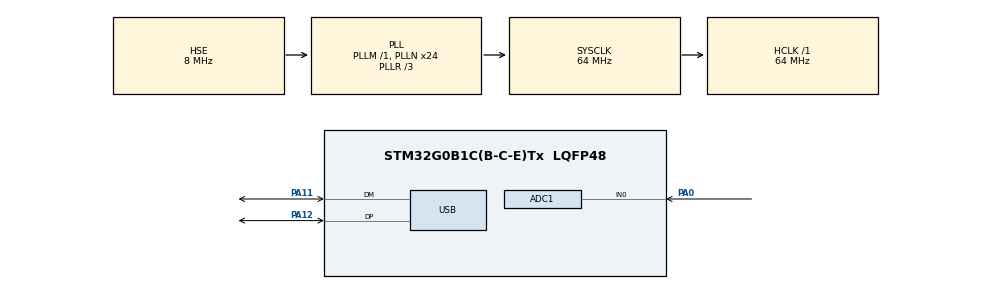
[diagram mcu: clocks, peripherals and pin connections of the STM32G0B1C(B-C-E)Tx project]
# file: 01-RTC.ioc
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ADC1.Channel-1\#ChannelRegularConversion=ADC_CHANNEL_0
ADC1.ContinuousConvMode=ENABLE
ADC1.DMAContinuousRequests=ENABLE
ADC1.NbrOfConversionFlag=1
ADC1.Rank-1\#ChannelRegularConversion=1
ADC1.SamplingTime-1\#ChannelRegularConversion=ADC_SAMPLINGTIME_COMMON_1
ADC1.SamplingTimeCommon1=ADC_SAMPLETIME_160CYCLES_5
ADC1.SamplingTimeCommon2=ADC_SAMPLETIME_160CYCLES_5
ADC1.SelectedChannel=ADC_CHANNEL_0
ADC1.master=1
Dma.ADC1.0.Direction=DMA_PERIPH_TO_MEMORY
Dma.ADC1.0.EventEnable=DISABLE
Dma.ADC1.0.Instance=DMA1_Channel1
Dma.ADC1.0.MemDataAlignment=DMA_MDATAALIGN_HALFWORD
Dma.ADC1.0.MemInc=DMA_MINC_ENABLE
Dma.ADC1.0.Mode=DMA_CIRCULAR
Dma.ADC1.0.PeriphDataAlignment=DMA_PDATAALIGN_HALFWORD
Dma.ADC1.0.PeriphInc=DMA_PINC_DISABLE
Dma.ADC1.0.Polarity=HAL_DMAMUX_REQ_GEN_RISING
Dma.ADC1.0.Priority=DMA_PRIORITY_LOW
Dma.ADC1.0.RequestNumber=1
Dma.ADC1.0.SignalID=NONE
Dma.ADC1.0.SyncEnable=DISABLE
Dma.ADC1.0.SyncPolarity=HAL_DMAMUX_SYNC_NO_EVENT
Dma.ADC1.0.SyncRequestNumber=1
Dma.ADC1.0.SyncSignalID=NONE
Dma.Request0=ADC1
Mcu.Family=STM32G0
Mcu.Name=STM32G0B1C(B-C-E)Tx
Mcu.Package=LQFP48
NVIC.DMA1_Channel1_IRQn=true\:0\:0\:false\:false\:true\:false\:true\:true
NVIC.USB_UCPD1_2_IRQn=true\:0\:0\:false\:false\:true\:true\:true\:true
PA0.Mode=IN0
PA0.Signal=ADC1_IN0
PA11\ [PA9].Mode=Device
PA11\ [PA9].Signal=USB_DM
PA12\ [PA10].Mode=Device
PA12\ [PA10].Signal=USB_DP
PA13.Mode=Serial_Wire
PA13.Signal=SYS_SWDIO
PA14-BOOT0.Mode=Serial_Wire
PA14-BOOT0.Signal=SYS_SWCLK
PC14-OSC32_IN\ (PC14).Mode=LSE-External-Oscillator
PC14-OSC32_IN\ (PC14).Signal=RCC_OSC32_IN
PC15-OSC32_OUT\ (PC15).Mode=LSE-External-Oscillator
PC15-OSC32_OUT\ (PC15).Signal=RCC_OSC32_OUT
PF0-OSC_IN\ (PF0).Mode=HSE-External-Oscillator
PF0-OSC_IN\ (PF0).Signal=RCC_OSC_IN
PF1-OSC_OUT\ (PF1).Mode=HSE-External-Oscillator
PF1-OSC_OUT\ (PF1).Signal=RCC_OSC_OUT
ProjectManager.HeapSize=0x400
ProjectManager.StackSize=0x400
ProjectManager.TargetToolchain=MDK-ARM V5.32
RCC.ADCFreq_Value=64000000
RCC.AHBFreq_Value=64000000
RCC.CortexFreq_Value=64000000
RCC.EXTERNAL_CLOCK_VALUE=48000
RCC.HCLKFreq_Value=64000000
RCC.HSE_VALUE=8000000
RCC.HSI48_VALUE=48000000
RCC.HSI_VALUE=16000000
RCC.LSE_Drive_Capability=RCC_LSEDRIVE_MEDIUMLOW
RCC.PLLN=24
RCC.PLLQ=RCC_PLLQ_DIV4
RCC.PLLR=RCC_PLLR_DIV3
RCC.PLLSourceVirtual=RCC_PLLSOURCE_HSE
RCC.RTCClockSelection=RCC_RTCCLKSOURCE_LSE
RCC.SYSCLKFreq_VALUE=64000000
RCC.SYSCLKSource=RCC_SYSCLKSOURCE_PLLCLK
RCC.USBCLockSelection=RCC_USBCLKSOURCE_PLL
RCC.USBFreq_Value=48000000
RCC.VCOOutputFreq_Value=192000000
RTC.Format=RTC_FORMAT_BIN
RTC.Month=RTC_MONTH_MARCH
RTC.WeekDay=RTC_WEEKDAY_FRIDAY
RTC.Year=24
USB_DEVICE.CLASS_NAME_FS=CDC
USB_DEVICE.VirtualMode=Cdc
USB_DEVICE.VirtualModeFS=Cdc_FS
VP_RTC_VS_RTC_Activate.Mode=RTC_Enabled
VP_RTC_VS_RTC_Calendar.Mode=RTC_Calendar
VP_SYS_VS_DBSignals.Mode=DisableDeadBatterySignals
VP_USB_DEVICE_VS_USB_DEVICE_CDC_FS.Mode=CDC_FS
board=custom

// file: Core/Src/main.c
/* USER CODE BEGIN Header */
/**
  ******************************************************************************
  * @file           : main.c
  * @brief          : Main program body
  ******************************************************************************
  * @attention
  *
  * Copyright (c) 2024 STMicroelectronics.
  * All rights reserved.
  *
  * This software is licensed under terms that can be found in the LICENSE file
  * in the root directory of this software component.
  * If no LICENSE file comes with this software, it is provided AS-IS.
  *
  ******************************************************************************
  */
/* USER CODE END Header */
#include "main.h"
#include "adc.h"
#include "dma.h"
#include "rtc.h"
#include "usb_device.h"
#include "gpio.h"

/* USER CODE BEGIN Includes */
#include "usbd_cdc_if.h"
#include <string.h>
#include <stdbool.h>
/* USER CODE END Includes */

void SystemClock_Config(void);

/* USER CODE BEGIN 0 */
void Flash_OB_Handle(void) {
	FLASH_OBProgramInitTypeDef optionsbytesstruct;
	bool UPDATE = false;

	HAL_FLASHEx_OBGetConfig(&optionsbytesstruct);
	uint32_t userconfig = optionsbytesstruct.USERConfig;

	if((userconfig & FLASH_OPTR_nBOOT_SEL_Msk) != OB_BOOT0_FROM_PIN) {
		userconfig &= ~FLASH_OPTR_nBOOT_SEL_Msk;
		userconfig |= OB_BOOT0_FROM_PIN;
		UPDATE = true;
	}

	if(UPDATE) {
		optionsbytesstruct.USERConfig = userconfig;
		HAL_FLASH_Unlock();
		HAL_FLASH_OB_Unlock();
		HAL_FLASHEx_OBProgram(&optionsbytesstruct);
		HAL_FLASH_OB_Launch();
		HAL_FLASH_OB_Lock();
		HAL_FLASH_Lock();
	}
}

uint16_t adc_inp;
/* USER CODE END 0 */

int main(void)
{

  /* MCU Configuration--------------------------------------------------------*/

  /* Reset of all peripherals, Initializes the Flash interface and the Systick. */
  HAL_Init();

  /* Configure the system clock */
  SystemClock_Config();

  /* USER CODE BEGIN SysInit */
	Flash_OB_Handle();
  /* USER CODE END SysInit */

  /* Initialize all configured peripherals */
  MX_GPIO_Init();
  MX_DMA_Init();
  MX_USB_Device_Init();
  MX_RTC_Init();
  MX_ADC1_Init();
  /* USER CODE BEGIN 2 */

	#include "board.h"
  board_button_init();
  board_led_init();

  uint32_t tick,tick_now;
  tick = HAL_GetTick() + 200;
  tick_now = HAL_GetTick();

	HAL_ADCEx_Calibration_Start(&hadc1);
	HAL_ADC_Start_DMA(&hadc1,(uint32_t *)&adc_inp,1);

  /* USER CODE END 2 */

  /* Infinite loop */
  while (1)
  {

    /* USER CODE BEGIN 3 */
		tick_now = HAL_GetTick();
    if(board_button_getstate())
    {
      if(tick_now >= tick)
      {
        tick = tick_now + 100;
        board_led_toggle();
      }
    }
    else
    {
      if(tick_now >= tick)
      {
        tick = tick_now + 500;

        RTC_DateTypeDef sdatestructureget;
        RTC_TimeTypeDef stimestructureget;
        uint8_t text[30];
        static uint8_t Seconds_o;
        int text_lenth;

        /* Get the RTC current Time */
        HAL_RTC_GetTime(&hrtc, &stimestructureget, RTC_FORMAT_BIN);
        /* Get the RTC current Date */
        HAL_RTC_GetDate(&hrtc, &sdatestructureget, RTC_FORMAT_BIN);

        if(Seconds_o != stimestructureget.Seconds)
        {
          Seconds_o = stimestructureget.Seconds;

          board_led_set(1);

          text_lenth = sprintf((char *) &text,"20%02d.%02d.%02d %02d:%02d %02d ,%d\r\n",sdatestructureget.Year,sdatestructureget.Month,sdatestructureget.Date, \
                                            stimestructureget.Hours,stimestructureget.Minutes,stimestructureget.Seconds,adc_inp);
          CDC_Transmit_FS(text,text_lenth);
        }
        else
        {
          board_led_set(0);
        }
      }
    }
  }
  /* USER CODE END 3 */
}

void SystemClock_Config(void)
{
  RCC_OscInitTypeDef RCC_OscInitStruct = {0};
  RCC_ClkInitTypeDef RCC_ClkInitStruct = {0};

  /** Configure the main internal regulator output voltage
  */
  HAL_PWREx_ControlVoltageScaling(PWR_REGULATOR_VOLTAGE_SCALE1);

  /** Configure LSE Drive Capability
  */
  HAL_PWR_EnableBkUpAccess();
  __HAL_RCC_LSEDRIVE_CONFIG(RCC_LSEDRIVE_MEDIUMLOW);

  /** Initializes the RCC Oscillators according to the specified parameters
  * in the RCC_OscInitTypeDef structure.
  */
  RCC_OscInitStruct.OscillatorType = RCC_OSCILLATORTYPE_HSE|RCC_OSCILLATORTYPE_LSE;
  RCC_OscInitStruct.HSEState = RCC_HSE_ON;
  RCC_OscInitStruct.LSEState = RCC_LSE_ON;
  RCC_OscInitStruct.PLL.PLLState = RCC_PLL_ON;
  RCC_OscInitStruct.PLL.PLLSource = RCC_PLLSOURCE_HSE;
  RCC_OscInitStruct.PLL.PLLM = RCC_PLLM_DIV1;
  RCC_OscInitStruct.PLL.PLLN = 24;
  RCC_OscInitStruct.PLL.PLLP = RCC_PLLP_DIV2;
  RCC_OscInitStruct.PLL.PLLQ = RCC_PLLQ_DIV4;
  RCC_OscInitStruct.PLL.PLLR = RCC_PLLR_DIV3;
  if (HAL_RCC_OscConfig(&RCC_OscInitStruct) != HAL_OK)
  {
    Error_Handler();
  }

  /** Initializes the CPU, AHB and APB buses clocks
  */
  RCC_ClkInitStruct.ClockType = RCC_CLOCKTYPE_HCLK|RCC_CLOCKTYPE_SYSCLK
                              |RCC_CLOCKTYPE_PCLK1;
  RCC_ClkInitStruct.SYSCLKSource = RCC_SYSCLKSOURCE_PLLCLK;
  RCC_ClkInitStruct.AHBCLKDivider = RCC_SYSCLK_DIV1;
  RCC_ClkInitStruct.APB1CLKDivider = RCC_HCLK_DIV1;

  if (HAL_RCC_ClockConfig(&RCC_ClkInitStruct, FLASH_LATENCY_2) != HAL_OK)
  {
    Error_Handler();
  }
}

void Error_Handler(void)
{
  __disable_irq();
  while (1)
  {
  }
}
